AUTOSAR XML (schema 314)
package /ComponentType
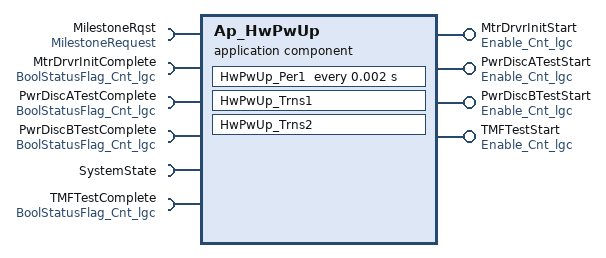
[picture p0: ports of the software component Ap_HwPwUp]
  application software component type Ap_HwPwUp
    4 x provide port, all with unqueued-sender-com-spec{data-element=Cnt_lgc, can-invalidate=false, init-value=D_FALSE_CNT_LGC}, provided-interface=Enable_Cnt_lgc:
      MtrDrvrInitStart
      PwrDiscATestStart
      PwrDiscBTestStart
      TMFTestStart
    6 x require port:
      MilestoneRqst: required-com-specs=[WarmInitMilestoneComplete, WarmInitMilestoneNotComplete], required-interface=MilestoneRequest
      MtrDrvrInitComplete: unqueued-receiver-com-spec{data-element=Cnt_lgc, init-value=D_FALSE_CNT_LGC}, required-interface=BoolStatusFlag_Cnt_lgc
      PwrDiscATestComplete: unqueued-receiver-com-spec{data-element=Cnt_lgc, init-value=D_FALSE_CNT_LGC}, required-interface=BoolStatusFlag_Cnt_lgc
      PwrDiscBTestComplete: unqueued-receiver-com-spec{data-element=Cnt_lgc, init-value=D_FALSE_CNT_LGC}, required-interface=BoolStatusFlag_Cnt_lgc
      SystemState: required-interface=SystemState
      TMFTestComplete: unqueued-receiver-com-spec{data-element=Cnt_lgc, init-value=D_FALSE_CNT_LGC}, required-interface=BoolStatusFlag_Cnt_lgc
  internal behavior Ap_HwPwUp_InternalBehavior: component=Ap_HwPwUp
    timing event TMT_HwPwUp_Per1: start-on-event=HwPwUp_Per1, period=0.002
    mode switch event MST_HwPwUp_Trns1_0: start-on-event=HwPwUp_Trns1, activation=EXIT, mode=SystemState.Mode.DISABLE
    mode switch event MST_HwPwUp_Trns1_1: start-on-event=HwPwUp_Trns1, activation=ENTRY, mode=SystemState.Mode.WARMINIT
    mode switch event MST_HwPwUp_Trns2_0: start-on-event=HwPwUp_Trns2, activation=ENTRY, mode=SystemState.Mode.DISABLE
    port-api-options:
      enable-take-address=false, indirect-api=false, port=MilestoneRqst
      enable-take-address=false, indirect-api=false, port=MtrDrvrInitComplete
      enable-take-address=false, indirect-api=false, port=MtrDrvrInitStart
      enable-take-address=false, indirect-api=false, port=PwrDiscATestComplete
      enable-take-address=false, indirect-api=false, port=PwrDiscATestStart
      enable-take-address=false, indirect-api=false, port=PwrDiscBTestComplete
      enable-take-address=false, indirect-api=false, port=PwrDiscBTestStart
      enable-take-address=false, indirect-api=false, port=SystemState
      enable-take-address=false, indirect-api=false, port=TMFTestComplete
      enable-take-address=false, indirect-api=false, port=TMFTestStart
    runnable HwPwUp_Per1
      4 x data read access:
        READ_MtrDrvrInitComplete_Cnt_lgc: data-element=MtrDrvrInitComplete.Cnt_lgc
        READ_PwrDiscATestComplete_Cnt_lgc: data-element=PwrDiscATestComplete.Cnt_lgc
        READ_PwrDiscBTestComplete_Cnt_lgc: data-element=PwrDiscBTestComplete.Cnt_lgc
        READ_TMFTestComplete_Cnt_lgc: data-element=TMFTestComplete.Cnt_lgc
      4 x data write access:
        WRITE_MtrDrvrInitStart_Cnt_lgc: data-element=MtrDrvrInitStart.Cnt_lgc
        WRITE_PwrDiscATestStart_Cnt_lgc: data-element=PwrDiscATestStart.Cnt_lgc
        WRITE_PwrDiscBTestStart_Cnt_lgc: data-element=PwrDiscBTestStart.Cnt_lgc
        WRITE_TMFTestStart_Cnt_lgc: data-element=TMFTestStart.Cnt_lgc
      sync call SC_MilestoneRqst_WarmInitMilestoneComplete: operation=MilestoneRqst.WarmInitMilestoneComplete, timeout=0
    runnable HwPwUp_Trns1
      4 x data write access:
        WRITE_MtrDrvrInitStart_Cnt_lgc: data-element=MtrDrvrInitStart.Cnt_lgc
        WRITE_PwrDiscATestStart_Cnt_lgc: data-element=PwrDiscATestStart.Cnt_lgc
        WRITE_PwrDiscBTestStart_Cnt_lgc: data-element=PwrDiscBTestStart.Cnt_lgc
        WRITE_TMFTestStart_Cnt_lgc: data-element=TMFTestStart.Cnt_lgc
      sync call SC_MilestoneRqst_WarmInitMilestoneNotComplete: operation=MilestoneRqst.WarmInitMilestoneNotComplete, timeout=0
    runnable HwPwUp_Trns2
  swc implementation Ap_HwPwUp_Implementation: behavior=Ap_HwPwUp_InternalBehavior
    code-descriptors:
      code Code: type=SRC
